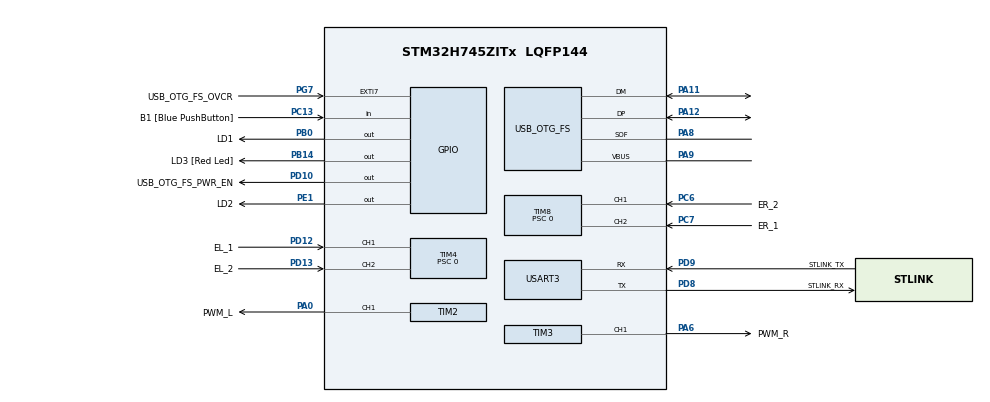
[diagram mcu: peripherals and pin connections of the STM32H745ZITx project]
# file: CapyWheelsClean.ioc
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CortexM4.IPs=FATFS_M4\:I,FREERTOS_M4\:I,IWDG2\:I,RCC,WWDG2\:I,DMA,BDMA,MDMA,NVIC2\:I,DEBUG,USB_DEVICE_M4\:I,USB_HOST_M4\:I,PDM2PCM_M4\:I,PWR,RESMGR_UTILITY,SYS_M4\:I,CORTEX_M4\:I,OPENAMP_M4\:I,VREFBUF,GPIO
CortexM7.IPs=FATFS_M7\:I,FREERTOS_M7\:I,IWDG1\:I,RCC\:I,WWDG1\:I,DMA\:I,BDMA\:I,MDMA\:I,NVIC1\:I,SYS\:I,USART3\:I,USB_OTG_FS\:I,CORTEX_M7\:I,DEBUG\:I,USB_DEVICE_M7\:I,USB_HOST_M7\:I,PDM2PCM_M7\:I,PWR\:I,RESMGR_UTILITY\:I,OPENAMP_M7\:I,VREFBUF\:I,GPIO\:I,TIM8\:I,TIM4\:I,TIM3\:I,TIM2\:I,TIM1\:I
CortexM7.Pins=PB0,PB14,PE1
Dma.Request0=USART3_RX
Dma.Request1=USART3_TX
Dma.USART3_RX.0.Direction=DMA_PERIPH_TO_MEMORY
Dma.USART3_RX.0.EventEnable=DISABLE
Dma.USART3_RX.0.FIFOMode=DMA_FIFOMODE_DISABLE
Dma.USART3_RX.0.Instance=DMA1_Stream0
Dma.USART3_RX.0.MemDataAlignment=DMA_MDATAALIGN_BYTE
Dma.USART3_RX.0.MemInc=DMA_MINC_ENABLE
Dma.USART3_RX.0.Mode=DMA_NORMAL
Dma.USART3_RX.0.PeriphDataAlignment=DMA_PDATAALIGN_BYTE
Dma.USART3_RX.0.PeriphInc=DMA_PINC_DISABLE
Dma.USART3_RX.0.Polarity=HAL_DMAMUX_REQ_GEN_RISING
Dma.USART3_RX.0.Priority=DMA_PRIORITY_LOW
Dma.USART3_RX.0.RequestNumber=1
Dma.USART3_RX.0.SignalID=NONE
Dma.USART3_RX.0.SyncEnable=DISABLE
Dma.USART3_RX.0.SyncPolarity=HAL_DMAMUX_SYNC_NO_EVENT
Dma.USART3_RX.0.SyncRequestNumber=1
Dma.USART3_RX.0.SyncSignalID=NONE
Dma.USART3_TX.1.Direction=DMA_MEMORY_TO_PERIPH
Dma.USART3_TX.1.EventEnable=DISABLE
Dma.USART3_TX.1.FIFOMode=DMA_FIFOMODE_DISABLE
Dma.USART3_TX.1.Instance=DMA1_Stream1
Dma.USART3_TX.1.MemDataAlignment=DMA_MDATAALIGN_BYTE
Dma.USART3_TX.1.MemInc=DMA_MINC_ENABLE
Dma.USART3_TX.1.Mode=DMA_NORMAL
Dma.USART3_TX.1.PeriphDataAlignment=DMA_PDATAALIGN_BYTE
Dma.USART3_TX.1.PeriphInc=DMA_PINC_DISABLE
Dma.USART3_TX.1.Polarity=HAL_DMAMUX_REQ_GEN_RISING
Dma.USART3_TX.1.Priority=DMA_PRIORITY_LOW
Dma.USART3_TX.1.RequestNumber=1
Dma.USART3_TX.1.SignalID=NONE
Dma.USART3_TX.1.SyncEnable=DISABLE
Dma.USART3_TX.1.SyncPolarity=HAL_DMAMUX_SYNC_NO_EVENT
Dma.USART3_TX.1.SyncRequestNumber=1
Dma.USART3_TX.1.SyncSignalID=NONE
Mcu.Family=STM32H7
Mcu.Name=STM32H745ZITx
Mcu.Package=LQFP144
NVIC1.DMA1_Stream0_IRQn=true\:0\:0\:false\:false\:true\:false\:true\:true
NVIC1.DMA1_Stream1_IRQn=true\:0\:0\:false\:false\:true\:false\:true\:true
NVIC1.PriorityGroup=NVIC_PRIORITYGROUP_4
NVIC1.TIM1_UP_IRQn=true\:0\:0\:false\:false\:true\:true\:true\:true
NVIC1.USART3_IRQn=true\:0\:0\:false\:false\:true\:true\:true\:true
NVIC2.PriorityGroup=NVIC_PRIORITYGROUP_4
PA0.GPIO_Label=PWM_L
PA0.GPIO_PuPd=GPIO_NOPULL
PA0.GPIO_Speed=GPIO_SPEED_FREQ_HIGH
PA0.PinAttribute=CortexM7
PA0.Signal=S_TIM2_CH1_ETR
PA1.PinAttribute=CortexM7
PA1.Signal=ETH_REF_CLK
PA11.Mode=Device_Only
PA11.PinAttribute=CortexM7
PA11.Signal=USB_OTG_FS_DM
PA12.Mode=Device_Only
PA12.PinAttribute=CortexM7
PA12.Signal=USB_OTG_FS_DP
PA2.PinAttribute=CortexM7
PA2.Signal=ETH_MDIO
PA6.GPIO_Label=PWM_R
PA6.GPIO_PuPd=GPIO_NOPULL
PA6.GPIO_Speed=GPIO_SPEED_FREQ_HIGH
PA6.PinAttribute=CortexM7
PA6.Signal=S_TIM3_CH1
PA7.PinAttribute=CortexM7
PA7.Signal=ETH_CRS_DV
PA8.Mode=Activate_SOF_FS
PA8.PinAttribute=CortexM7
PA8.Signal=USB_OTG_FS_SOF
PA9.Mode=Activate_VBUS
PA9.PinAttribute=CortexM7
PA9.Signal=USB_OTG_FS_VBUS
PB0.GPIO_Label=LD1
PB0.GPIO_PuPd=GPIO_PULLUP
PB0.GPIO_Speed=GPIO_SPEED_FREQ_HIGH
PB0.PinAttribute=CortexM7
PB0.PinState=GPIO_PIN_RESET
PB0.Signal=GPIO_Output
PB13.PinAttribute=CortexM7
PB13.Signal=ETH_TXD1
PB14.GPIO_Label=LD3 [Red Led]
PB14.GPIO_PuPd=GPIO_PULLUP
PB14.GPIO_Speed=GPIO_SPEED_FREQ_HIGH
PB14.PinAttribute=CortexM7
PB14.PinState=GPIO_PIN_RESET
PB14.Signal=GPIO_Output
PC1.PinAttribute=CortexM7
PC1.Signal=ETH_MDC
PC13.GPIO_Label=B1 [Blue PushButton]
PC13.PinAttribute=Free
PC13.Signal=GPIO_Input
PC14-OSC32_IN\ (OSC32_IN).Mode=LSE-External-Oscillator
PC14-OSC32_IN\ (OSC32_IN).PinAttribute=CortexM7
PC14-OSC32_IN\ (OSC32_IN).Signal=RCC_OSC32_IN
PC15-OSC32_OUT\ (OSC32_OUT).Mode=LSE-External-Oscillator
PC15-OSC32_OUT\ (OSC32_OUT).PinAttribute=CortexM7
PC15-OSC32_OUT\ (OSC32_OUT).Signal=RCC_OSC32_OUT
PC4.PinAttribute=CortexM7
PC4.Signal=ETH_RXD0
PC5.PinAttribute=CortexM7
PC5.Signal=ETH_RXD1
PC6.GPIO_Label=ER_2
PC6.GPIO_PuPd=GPIO_PULLUP
PC6.GPIO_Speed=GPIO_SPEED_FREQ_HIGH
PC6.PinAttribute=CortexM7
PC6.Signal=S_TIM8_CH1
PC7.GPIO_Label=ER_1
PC7.GPIO_PuPd=GPIO_PULLUP
PC7.GPIO_Speed=GPIO_SPEED_FREQ_HIGH
PC7.PinAttribute=CortexM7
PC7.Signal=S_TIM8_CH2
PD10.GPIO_Label=USB_OTG_FS_PWR_EN
PD10.PinAttribute=Free
PD10.Signal=GPIO_Output
PD12.GPIO_Label=EL_1
PD12.GPIO_PuPd=GPIO_PULLUP
PD12.GPIO_Speed=GPIO_SPEED_FREQ_HIGH
PD12.PinAttribute=CortexM7
PD12.Signal=S_TIM4_CH1
PD13.GPIO_Label=EL_2
PD13.GPIO_PuPd=GPIO_PULLUP
PD13.GPIO_Speed=GPIO_SPEED_FREQ_HIGH
PD13.PinAttribute=CortexM7
PD13.Signal=S_TIM4_CH2
PD8.GPIO_Label=STLINK_RX
PD8.Mode=Asynchronous
PD8.PinAttribute=CortexM7
PD8.Signal=USART3_TX
PD9.GPIO_Label=STLINK_TX
PD9.Mode=Asynchronous
PD9.PinAttribute=CortexM7
PD9.Signal=USART3_RX
PE1.GPIO_Label=LD2
PE1.GPIO_PuPd=GPIO_PULLUP
PE1.GPIO_Speed=GPIO_SPEED_FREQ_HIGH
PE1.PinAttribute=CortexM7
PE1.PinState=GPIO_PIN_RESET
PE1.Signal=GPIO_Output
PG11.PinAttribute=CortexM7
PG11.Signal=ETH_TX_EN
PG13.PinAttribute=CortexM7
PG13.Signal=ETH_TXD0
PG7.GPIO_Label=USB_OTG_FS_OVCR
PG7.PinAttribute=Free
PG7.Signal=GPXTI7
PH0-OSC_IN\ (PH0).Mode=HSE-External-Clock-Source
PH0-OSC_IN\ (PH0).PinAttribute=CortexM7
PH0-OSC_IN\ (PH0).Signal=RCC_OSC_IN
PH1-OSC_OUT\ (PH1).PinAttribute=CortexM7
PH1-OSC_OUT\ (PH1).Signal=RCC_OSC_OUT
ProjectManager.HeapSize=M4-0x200,M7-0x200
ProjectManager.StackSize=M4-0x400,M7-0x400
ProjectManager.TargetToolchain=STM32CubeIDE
RCC.ADCFreq_Value=16125000
RCC.APB1Freq_Value=37500000
RCC.APB2Freq_Value=37500000
RCC.APB3Freq_Value=37500000
RCC.APB4Freq_Value=37500000
RCC.CortexFreq_Value=75000000
RCC.D1PPRE=RCC_APB3_DIV2
RCC.D2PPRE1=RCC_APB1_DIV2
RCC.D2PPRE2=RCC_APB2_DIV2
RCC.D3PPRE=RCC_APB4_DIV2
RCC.DIVM1=1
RCC.DIVM3=1
RCC.DIVN1=18
RCC.DIVN3=18
RCC.DIVQ3=3
RCC.HCLKFreq_Value=75000000
RCC.HSE_VALUE=8000000
RCC.PLL2FRACN=0
RCC.PLL3FRACN=6144
RCC.PLLFRACN=6144
RCC.SYSCLKFreq_VALUE=75000000
RCC.SYSCLKSource=RCC_SYSCLKSOURCE_PLLCLK
RCC.SupplySource=PWR_DIRECT_SMPS_SUPPLY
RCC.USBCLockSelection=RCC_USBCLKSOURCE_PLL3
RCC.USBFreq_Value=50000000
SH.S_TIM2_CH1_ETR.0=TIM2_CH1,PWM Generation1 CH1
SH.S_TIM3_CH1.0=TIM3_CH1,PWM Generation1 CH1
SH.S_TIM4_CH1.0=TIM4_CH1,Encoder_Interface
SH.S_TIM4_CH2.0=TIM4_CH2,Encoder_Interface
SH.S_TIM8_CH1.0=TIM8_CH1,Encoder_Interface
SH.S_TIM8_CH2.0=TIM8_CH2,Encoder_Interface
TIM1.AutoReloadPreload=TIM_AUTORELOAD_PRELOAD_ENABLE
TIM1.Period=20000
TIM1.Prescaler=74
TIM2.AutoReloadPreload=TIM_AUTORELOAD_PRELOAD_ENABLE
TIM2.Channel-PWM\ Generation1\ CH1=TIM_CHANNEL_1
TIM2.Period=1950
TIM2.Prescaler=75
TIM3.AutoReloadPreload=TIM_AUTORELOAD_PRELOAD_ENABLE
TIM3.Channel-PWM\ Generation1\ CH1=TIM_CHANNEL_1
TIM3.Period=1950
TIM3.Prescaler=75
TIM4.AutoReloadPreload=TIM_AUTORELOAD_PRELOAD_ENABLE
TIM4.EncoderMode=TIM_ENCODERMODE_TI12
TIM4.IC1Filter=1
TIM4.IC1Polarity=TIM_ICPOLARITY_FALLING
TIM4.IC2Filter=1
TIM4.IC2Polarity=TIM_ICPOLARITY_FALLING
TIM4.Period=538
TIM4.Prescaler=0
TIM4.TIM_MasterOutputTrigger=TIM_TRGO_RESET
TIM8.AutoReloadPreload=TIM_AUTORELOAD_PRELOAD_ENABLE
TIM8.EncoderMode=TIM_ENCODERMODE_TI12
TIM8.IC1Filter=1
TIM8.IC2Filter=1
TIM8.Period=538
TIM8.Prescaler=0
USART3.VirtualMode-Asynchronous=VM_ASYNC
USB_OTG_FS.VirtualMode=Device_Only
VP_SYS_M4_VS_Systick.Mode=SysTick
VP_TIM1_VS_ClockSourceINT.Mode=Internal
VP_TIM2_VS_ClockSourceINT.Mode=Internal
VP_TIM3_VS_ClockSourceINT.Mode=Internal
board=NUCLEO-H745ZI-Q

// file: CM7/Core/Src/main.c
/* USER CODE BEGIN Header */
/**
  ******************************************************************************
  * @file           : main.c
  * @brief          : Main program body
  ******************************************************************************
  * @attention
  *
  * Copyright (c) 2023 STMicroelectronics.
  * All rights reserved.
  *
  * This software is licensed under terms that can be found in the LICENSE file
  * in the root directory of this software component.
  * If no LICENSE file comes with this software, it is provided AS-IS.
  *
  ******************************************************************************
  */
/* USER CODE END Header */
#include "main.h"

/* USER CODE BEGIN Includes */
#include "mainpp.h"
/* USER CODE END Includes */

/* USER CODE BEGIN PD */

#ifndef HSEM_ID_0
#define HSEM_ID_0 (0U) /* HW semaphore 0*/
#endif

/* USER CODE END PD */

TIM_HandleTypeDef htim1;
TIM_HandleTypeDef htim2;
TIM_HandleTypeDef htim3;
TIM_HandleTypeDef htim4;
TIM_HandleTypeDef htim8;

UART_HandleTypeDef huart3;
DMA_HandleTypeDef hdma_usart3_rx;
DMA_HandleTypeDef hdma_usart3_tx;

PCD_HandleTypeDef hpcd_USB_OTG_FS;

/* USER CODE BEGIN PV */

// NOTE: YOU SHOULD CHANGE THIS DEPENDING ON THE
// FREQUENCY YOU READ THE ENCODER
float EncoderReadoutPeriod = 0.005;
/* USER CODE END PV */

void SystemClock_Config(void);
static void MX_GPIO_Init(void);
static void MX_DMA_Init(void);
static void MX_USART3_UART_Init(void);
static void MX_USB_OTG_FS_PCD_Init(void);
static void MX_TIM8_Init(void);
static void MX_TIM4_Init(void);
static void MX_TIM2_Init(void);
static void MX_TIM3_Init(void);
static void MX_TIM1_Init(void);

int main(void)
{
/* USER CODE BEGIN Boot_Mode_Sequence_0 */
  int32_t timeout;
/* USER CODE END Boot_Mode_Sequence_0 */

/* USER CODE BEGIN Boot_Mode_Sequence_1 */
  /* Wait until CPU2 boots and enters in stop mode or timeout*/
  timeout = 0xFFFF;
  while((__HAL_RCC_GET_FLAG(RCC_FLAG_D2CKRDY) != RESET) && (timeout-- > 0));
  if ( timeout < 0 )
  {
  Error_Handler();
  }
/* USER CODE END Boot_Mode_Sequence_1 */
  /* MCU Configuration--------------------------------------------------------*/

  /* Reset of all peripherals, Initializes the Flash interface and the Systick. */
  HAL_Init();

  /* Configure the system clock */
  SystemClock_Config();
/* USER CODE BEGIN Boot_Mode_Sequence_2 */
/* When system initialization is finished, Cortex-M7 will release Cortex-M4 by means of
HSEM notification */
/*HW semaphore Clock enable*/
__HAL_RCC_HSEM_CLK_ENABLE();
/*Take HSEM */
HAL_HSEM_FastTake(HSEM_ID_0);
/*Release HSEM in order to notify the CPU2(CM4)*/
HAL_HSEM_Release(HSEM_ID_0,0);
/* wait until CPU2 wakes up from stop mode */
timeout = 0xFFFF;
while((__HAL_RCC_GET_FLAG(RCC_FLAG_D2CKRDY) == RESET) && (timeout-- > 0));
if ( timeout < 0 )
{
Error_Handler();
}
/* USER CODE END Boot_Mode_Sequence_2 */

  /* Initialize all configured peripherals */
  MX_GPIO_Init();
  MX_DMA_Init();
  MX_USART3_UART_Init();
  MX_USB_OTG_FS_PCD_Init();
  MX_TIM8_Init();
  MX_TIM4_Init();
  MX_TIM2_Init();
  MX_TIM3_Init();
  MX_TIM1_Init();
  /* USER CODE BEGIN 2 */

  // Init timer for delta time response with interrupts
  //HAL_TIM_Base_Start_IT(&htim1);
  // Init PWM timers
  HAL_TIM_PWM_Start(&htim2, TIM_CHANNEL_1);
  HAL_TIM_PWM_Start(&htim3, TIM_CHANNEL_1);

  // Init encoders
  HAL_TIM_Base_Start_IT(&htim1);

  HAL_TIM_Encoder_Start_IT(&htim4, TIM_CHANNEL_ALL);
  HAL_TIM_Encoder_Start_IT(&htim8, TIM_CHANNEL_ALL);

  //__HAL_TIM_ENABLE_IT(&htim1, TIM_IT_UPDATE);
  //__HAL_TIM_ENABLE_IT(&htim4, TIM_IT_TRIGGER);
  //__HAL_TIM_ENABLE_IT(&htim8, TIM_IT_UPDATE);
  	  /* Tried:
  	   * TIM_IT_CC1 -> failed
  	   * TIM_IT_CC2 -> failed
  	   * TIM_IT_CC3 -> failed
  	   * TIM_IT_CC4 -Z failed
  	   * TIM_IT_UPDATE -> weird data
  	   * TIM_IT_COM -> failed
  	   * TIM_IT_TRIGGER -> failed
  	   * TIM_IT_BREAK -> failed
  	   */
  //__HAL_TIM_ENABLE_IT(&htim4, TIM_IT_UPDATE);
  //__HAL_TIM_ENABLE_IT(&htim8, TIM_IT_CC1 );

  // Setup Node handler
  setup();
  /* USER CODE END 2 */

  /* Infinite loop */
  while (1)
  {

    /* USER CODE BEGIN 3 */
	  loop();
	  /*
	  tickCount_r = TIM1 -> CNT;
	  uart_buf_len = sprintf(uart_buf, "%u ticks\r\n", tickCount_r);
	  HAL_UART_Transmit(&huart3, (uint8_t *)uart_buf, uart_buf_len, 100);
	  */
  }
  /* USER CODE END 3 */
}

void SystemClock_Config(void)
{
  RCC_OscInitTypeDef RCC_OscInitStruct = {0};
  RCC_ClkInitTypeDef RCC_ClkInitStruct = {0};

  /** Supply configuration update enable
  */
  HAL_PWREx_ConfigSupply(PWR_DIRECT_SMPS_SUPPLY);

  /** Configure the main internal regulator output voltage
  */
  __HAL_PWR_VOLTAGESCALING_CONFIG(PWR_REGULATOR_VOLTAGE_SCALE3);

  while(!__HAL_PWR_GET_FLAG(PWR_FLAG_VOSRDY)) {}

  /** Initializes the RCC Oscillators according to the specified parameters
  * in the RCC_OscInitTypeDef structure.
  */
  RCC_OscInitStruct.OscillatorType = RCC_OSCILLATORTYPE_HSE;
  RCC_OscInitStruct.HSEState = RCC_HSE_BYPASS;
  RCC_OscInitStruct.PLL.PLLState = RCC_PLL_ON;
  RCC_OscInitStruct.PLL.PLLSource = RCC_PLLSOURCE_HSE;
  RCC_OscInitStruct.PLL.PLLM = 1;
  RCC_OscInitStruct.PLL.PLLN = 18;
  RCC_OscInitStruct.PLL.PLLP = 2;
  RCC_OscInitStruct.PLL.PLLQ = 2;
  RCC_OscInitStruct.PLL.PLLR = 2;
  RCC_OscInitStruct.PLL.PLLRGE = RCC_PLL1VCIRANGE_3;
  RCC_OscInitStruct.PLL.PLLVCOSEL = RCC_PLL1VCOMEDIUM;
  RCC_OscInitStruct.PLL.PLLFRACN = 6144;
  if (HAL_RCC_OscConfig(&RCC_OscInitStruct) != HAL_OK)
  {
    Error_Handler();
  }

  /** Initializes the CPU, AHB and APB buses clocks
  */
  RCC_ClkInitStruct.ClockType = RCC_CLOCKTYPE_HCLK|RCC_CLOCKTYPE_SYSCLK
                              |RCC_CLOCKTYPE_PCLK1|RCC_CLOCKTYPE_PCLK2
                              |RCC_CLOCKTYPE_D3PCLK1|RCC_CLOCKTYPE_D1PCLK1;
  RCC_ClkInitStruct.SYSCLKSource = RCC_SYSCLKSOURCE_PLLCLK;
  RCC_ClkInitStruct.SYSCLKDivider = RCC_SYSCLK_DIV1;
  RCC_ClkInitStruct.AHBCLKDivider = RCC_HCLK_DIV1;
  RCC_ClkInitStruct.APB3CLKDivider = RCC_APB3_DIV2;
  RCC_ClkInitStruct.APB1CLKDivider = RCC_APB1_DIV2;
  RCC_ClkInitStruct.APB2CLKDivider = RCC_APB2_DIV2;
  RCC_ClkInitStruct.APB4CLKDivider = RCC_APB4_DIV2;

  if (HAL_RCC_ClockConfig(&RCC_ClkInitStruct, FLASH_LATENCY_1) != HAL_OK)
  {
    Error_Handler();
  }
}

static void MX_TIM1_Init(void)
{

  TIM_ClockConfigTypeDef sClockSourceConfig = {0};
  TIM_MasterConfigTypeDef sMasterConfig = {0};

  htim1.Instance = TIM1;
  htim1.Init.Prescaler = 74;
  htim1.Init.CounterMode = TIM_COUNTERMODE_UP;
  htim1.Init.Period = 20000;
  htim1.Init.ClockDivision = TIM_CLOCKDIVISION_DIV1;
  htim1.Init.RepetitionCounter = 0;
  htim1.Init.AutoReloadPreload = TIM_AUTORELOAD_PRELOAD_ENABLE;
  if (HAL_TIM_Base_Init(&htim1) != HAL_OK)
  {
    Error_Handler();
  }
  sClockSourceConfig.ClockSource = TIM_CLOCKSOURCE_INTERNAL;
  if (HAL_TIM_ConfigClockSource(&htim1, &sClockSourceConfig) != HAL_OK)
  {
    Error_Handler();
  }
  sMasterConfig.MasterOutputTrigger = TIM_TRGO_RESET;
  sMasterConfig.MasterOutputTrigger2 = TIM_TRGO2_RESET;
  sMasterConfig.MasterSlaveMode = TIM_MASTERSLAVEMODE_DISABLE;
  if (HAL_TIMEx_MasterConfigSynchronization(&htim1, &sMasterConfig) != HAL_OK)
  {
    Error_Handler();
  }

}

static void MX_TIM2_Init(void)
{

  TIM_ClockConfigTypeDef sClockSourceConfig = {0};
  TIM_MasterConfigTypeDef sMasterConfig = {0};
  TIM_OC_InitTypeDef sConfigOC = {0};

  htim2.Instance = TIM2;
  htim2.Init.Prescaler = 75;
  htim2.Init.CounterMode = TIM_COUNTERMODE_UP;
  htim2.Init.Period = 1950;
  htim2.Init.ClockDivision = TIM_CLOCKDIVISION_DIV1;
  htim2.Init.AutoReloadPreload = TIM_AUTORELOAD_PRELOAD_ENABLE;
  if (HAL_TIM_Base_Init(&htim2) != HAL_OK)
  {
    Error_Handler();
  }
  sClockSourceConfig.ClockSource = TIM_CLOCKSOURCE_INTERNAL;
  if (HAL_TIM_ConfigClockSource(&htim2, &sClockSourceConfig) != HAL_OK)
  {
    Error_Handler();
  }
  if (HAL_TIM_PWM_Init(&htim2) != HAL_OK)
  {
    Error_Handler();
  }
  sMasterConfig.MasterOutputTrigger = TIM_TRGO_RESET;
  sMasterConfig.MasterSlaveMode = TIM_MASTERSLAVEMODE_DISABLE;
  if (HAL_TIMEx_MasterConfigSynchronization(&htim2, &sMasterConfig) != HAL_OK)
  {
    Error_Handler();
  }
  sConfigOC.OCMode = TIM_OCMODE_PWM1;
  sConfigOC.Pulse = 0;
  sConfigOC.OCPolarity = TIM_OCPOLARITY_HIGH;
  sConfigOC.OCFastMode = TIM_OCFAST_DISABLE;
  if (HAL_TIM_PWM_ConfigChannel(&htim2, &sConfigOC, TIM_CHANNEL_1) != HAL_OK)
  {
    Error_Handler();
  }
  HAL_TIM_MspPostInit(&htim2);

}

static void MX_TIM3_Init(void)
{

  TIM_ClockConfigTypeDef sClockSourceConfig = {0};
  TIM_MasterConfigTypeDef sMasterConfig = {0};
  TIM_OC_InitTypeDef sConfigOC = {0};

  htim3.Instance = TIM3;
  htim3.Init.Prescaler = 75;
  htim3.Init.CounterMode = TIM_COUNTERMODE_UP;
  htim3.Init.Period = 1950;
  htim3.Init.ClockDivision = TIM_CLOCKDIVISION_DIV1;
  htim3.Init.AutoReloadPreload = TIM_AUTORELOAD_PRELOAD_ENABLE;
  if (HAL_TIM_Base_Init(&htim3) != HAL_OK)
  {
    Error_Handler();
  }
  sClockSourceConfig.ClockSource = TIM_CLOCKSOURCE_INTERNAL;
  if (HAL_TIM_ConfigClockSource(&htim3, &sClockSourceConfig) != HAL_OK)
  {
    Error_Handler();
  }
  if (HAL_TIM_PWM_Init(&htim3) != HAL_OK)
  {
    Error_Handler();
  }
  sMasterConfig.MasterOutputTrigger = TIM_TRGO_RESET;
  sMasterConfig.MasterSlaveMode = TIM_MASTERSLAVEMODE_DISABLE;
  if (HAL_TIMEx_MasterConfigSynchronization(&htim3, &sMasterConfig) != HAL_OK)
  {
    Error_Handler();
  }
  sConfigOC.OCMode = TIM_OCMODE_PWM1;
  sConfigOC.Pulse = 0;
  sConfigOC.OCPolarity = TIM_OCPOLARITY_HIGH;
  sConfigOC.OCFastMode = TIM_OCFAST_DISABLE;
  if (HAL_TIM_PWM_ConfigChannel(&htim3, &sConfigOC, TIM_CHANNEL_1) != HAL_OK)
  {
    Error_Handler();
  }
  HAL_TIM_MspPostInit(&htim3);

}

static void MX_TIM4_Init(void)
{

  TIM_Encoder_InitTypeDef sConfig = {0};
  TIM_MasterConfigTypeDef sMasterConfig = {0};

  htim4.Instance = TIM4;
  htim4.Init.Prescaler = 0;
  htim4.Init.CounterMode = TIM_COUNTERMODE_UP;
  htim4.Init.Period = 538;
  htim4.Init.ClockDivision = TIM_CLOCKDIVISION_DIV1;
  htim4.Init.AutoReloadPreload = TIM_AUTORELOAD_PRELOAD_ENABLE;
  sConfig.EncoderMode = TIM_ENCODERMODE_TI12;
  sConfig.IC1Polarity = TIM_ICPOLARITY_FALLING;
  sConfig.IC1Selection = TIM_ICSELECTION_DIRECTTI;
  sConfig.IC1Prescaler = TIM_ICPSC_DIV1;
  sConfig.IC1Filter = 1;
  sConfig.IC2Polarity = TIM_ICPOLARITY_FALLING;
  sConfig.IC2Selection = TIM_ICSELECTION_DIRECTTI;
  sConfig.IC2Prescaler = TIM_ICPSC_DIV1;
  sConfig.IC2Filter = 1;
  if (HAL_TIM_Encoder_Init(&htim4, &sConfig) != HAL_OK)
  {
    Error_Handler();
  }
  sMasterConfig.MasterOutputTrigger = TIM_TRGO_RESET;
  sMasterConfig.MasterSlaveMode = TIM_MASTERSLAVEMODE_DISABLE;
  if (HAL_TIMEx_MasterConfigSynchronization(&htim4, &sMasterConfig) != HAL_OK)
  {
    Error_Handler();
  }

}

static void MX_TIM8_Init(void)
{

  TIM_Encoder_InitTypeDef sConfig = {0};
  TIM_MasterConfigTypeDef sMasterConfig = {0};

  htim8.Instance = TIM8;
  htim8.Init.Prescaler = 0;
  htim8.Init.CounterMode = TIM_COUNTERMODE_UP;
  htim8.Init.Period = 538;
  htim8.Init.ClockDivision = TIM_CLOCKDIVISION_DIV1;
  htim8.Init.RepetitionCounter = 0;
  htim8.Init.AutoReloadPreload = TIM_AUTORELOAD_PRELOAD_ENABLE;
  sConfig.EncoderMode = TIM_ENCODERMODE_TI12;
  sConfig.IC1Polarity = TIM_ICPOLARITY_RISING;
  sConfig.IC1Selection = TIM_ICSELECTION_DIRECTTI;
  sConfig.IC1Prescaler = TIM_ICPSC_DIV1;
  sConfig.IC1Filter = 1;
  sConfig.IC2Polarity = TIM_ICPOLARITY_RISING;
  sConfig.IC2Selection = TIM_ICSELECTION_DIRECTTI;
  sConfig.IC2Prescaler = TIM_ICPSC_DIV1;
  sConfig.IC2Filter = 1;
  if (HAL_TIM_Encoder_Init(&htim8, &sConfig) != HAL_OK)
  {
    Error_Handler();
  }
  sMasterConfig.MasterOutputTrigger = TIM_TRGO_RESET;
  sMasterConfig.MasterOutputTrigger2 = TIM_TRGO2_RESET;
  sMasterConfig.MasterSlaveMode = TIM_MASTERSLAVEMODE_DISABLE;
  if (HAL_TIMEx_MasterConfigSynchronization(&htim8, &sMasterConfig) != HAL_OK)
  {
    Error_Handler();
  }

}

static void MX_USART3_UART_Init(void)
{

  huart3.Instance = USART3;
  huart3.Init.BaudRate = 115200;
  huart3.Init.WordLength = UART_WORDLENGTH_8B;
  huart3.Init.StopBits = UART_STOPBITS_1;
  huart3.Init.Parity = UART_PARITY_NONE;
  huart3.Init.Mode = UART_MODE_TX_RX;
  huart3.Init.HwFlowCtl = UART_HWCONTROL_NONE;
  huart3.Init.OverSampling = UART_OVERSAMPLING_16;
  huart3.Init.OneBitSampling = UART_ONE_BIT_SAMPLE_DISABLE;
  huart3.Init.ClockPrescaler = UART_PRESCALER_DIV1;
  huart3.AdvancedInit.AdvFeatureInit = UART_ADVFEATURE_NO_INIT;
  if (HAL_UART_Init(&huart3) != HAL_OK)
  {
    Error_Handler();
  }
  if (HAL_UARTEx_SetTxFifoThreshold(&huart3, UART_TXFIFO_THRESHOLD_1_8) != HAL_OK)
  {
    Error_Handler();
  }
  if (HAL_UARTEx_SetRxFifoThreshold(&huart3, UART_RXFIFO_THRESHOLD_1_8) != HAL_OK)
  {
    Error_Handler();
  }
  if (HAL_UARTEx_DisableFifoMode(&huart3) != HAL_OK)
  {
    Error_Handler();
  }

}

static void MX_USB_OTG_FS_PCD_Init(void)
{

  hpcd_USB_OTG_FS.Instance = USB_OTG_FS;
  hpcd_USB_OTG_FS.Init.dev_endpoints = 9;
  hpcd_USB_OTG_FS.Init.speed = PCD_SPEED_FULL;
  hpcd_USB_OTG_FS.Init.dma_enable = DISABLE;
  hpcd_USB_OTG_FS.Init.phy_itface = PCD_PHY_EMBEDDED;
  hpcd_USB_OTG_FS.Init.Sof_enable = DISABLE;
  hpcd_USB_OTG_FS.Init.low_power_enable = DISABLE;
  hpcd_USB_OTG_FS.Init.lpm_enable = DISABLE;
  hpcd_USB_OTG_FS.Init.battery_charging_enable = ENABLE;
  hpcd_USB_OTG_FS.Init.vbus_sensing_enable = ENABLE;
  hpcd_USB_OTG_FS.Init.use_dedicated_ep1 = DISABLE;
  if (HAL_PCD_Init(&hpcd_USB_OTG_FS) != HAL_OK)
  {
    Error_Handler();
  }

}

static void MX_DMA_Init(void)
{

  /* DMA controller clock enable */
  __HAL_RCC_DMA1_CLK_ENABLE();

  /* DMA interrupt init */
  /* DMA1_Stream0_IRQn interrupt configuration */
  HAL_NVIC_SetPriority(DMA1_Stream0_IRQn, 0, 0);
  HAL_NVIC_EnableIRQ(DMA1_Stream0_IRQn);
  /* DMA1_Stream1_IRQn interrupt configuration */
  HAL_NVIC_SetPriority(DMA1_Stream1_IRQn, 0, 0);
  HAL_NVIC_EnableIRQ(DMA1_Stream1_IRQn);

}

static void MX_GPIO_Init(void)
{
  GPIO_InitTypeDef GPIO_InitStruct = {0};

  /* GPIO Ports Clock Enable */
  __HAL_RCC_GPIOC_CLK_ENABLE();
  __HAL_RCC_GPIOH_CLK_ENABLE();
  __HAL_RCC_GPIOA_CLK_ENABLE();
  __HAL_RCC_GPIOB_CLK_ENABLE();
  __HAL_RCC_GPIOD_CLK_ENABLE();
  __HAL_RCC_GPIOE_CLK_ENABLE();

  /*Configure GPIO pin Output Level */
  HAL_GPIO_WritePin(GPIOB, LD1_Pin|LD3_Pin, GPIO_PIN_RESET);

  /*Configure GPIO pin Output Level */
  HAL_GPIO_WritePin(LD2_GPIO_Port, LD2_Pin, GPIO_PIN_RESET);

  /*Configure GPIO pins : LD1_Pin LD3_Pin */
  GPIO_InitStruct.Pin = LD1_Pin|LD3_Pin;
  GPIO_InitStruct.Mode = GPIO_MODE_OUTPUT_PP;
  GPIO_InitStruct.Pull = GPIO_PULLUP;
  GPIO_InitStruct.Speed = GPIO_SPEED_FREQ_HIGH;
  HAL_GPIO_Init(GPIOB, &GPIO_InitStruct);

  /*Configure GPIO pin : LD2_Pin */
  GPIO_InitStruct.Pin = LD2_Pin;
  GPIO_InitStruct.Mode = GPIO_MODE_OUTPUT_PP;
  GPIO_InitStruct.Pull = GPIO_PULLUP;
  GPIO_InitStruct.Speed = GPIO_SPEED_FREQ_HIGH;
  HAL_GPIO_Init(LD2_GPIO_Port, &GPIO_InitStruct);

}

/* USER CODE BEGIN 4 */

	// Callback for interruption
	// The name for this function is declared somewhere else in the project
void HAL_TIM_PeriodElapsedCallback(TIM_HandleTypeDef * htim){
	// Since this funcion can be called by any timer, we first check the
	// interrupt originated from the TIM1
	if (htim == &htim1){
		//resetEncoder();
	}
/*
	if (htim == &htim4){
		readEncoderVelWl ();
		//HAL_GPIO_TogglePin (GPIOE, GPIO_PIN_1);  // yellow LED

	}
	if (htim == &htim8){
		readEncoderVelWr ();
		//HAL_GPIO_TogglePin (GPIOB, GPIO_PIN_14); // RED LED
	}

	if (htim == &htim8){
			readEncoderVelWr ();
			//HAL_GPIO_TogglePin (GPIOB, GPIO_PIN_14); // RED LED
		}
		*/
}
void HAL_TIM_IC_CaptureCallback  (TIM_HandleTypeDef * htim){
	// HAL_TIM_TriggerCallback -> FAILED
	if (htim == &htim4){
		//readEncoderVelWl ();
	}

}

/* USER CODE END 4 */

void Error_Handler(void)
{
  __disable_irq();
  while (1)
  {
  }
}
